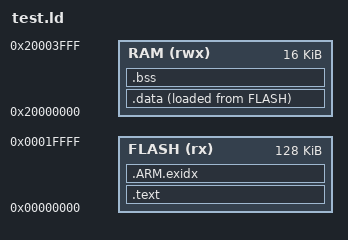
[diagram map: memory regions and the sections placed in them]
/* Test-only map shared by the selected QEMU machines, not a production MCU map. */
ENTRY(Reset_Handler)
MEMORY {
  FLASH(rx) : ORIGIN = 0x00000000, LENGTH = 128K
  RAM(rwx) : ORIGIN = 0x20000000, LENGTH = 16K
}
_estack = ORIGIN(RAM) + LENGTH(RAM);
SECTIONS {
  .text : { KEEP(*(.isr_vector)) *(.text*) *(.rodata*) } > FLASH
  .ARM.exidx : { *(.ARM.exidx*) } > FLASH
  .data : { . = ALIGN(4); _sdata = .; *(.data*) . = ALIGN(4); _edata = .; } > RAM AT> FLASH
  _sidata = LOADADDR(.data);
  .bss (NOLOAD) : { . = ALIGN(4); _sbss = .; *(.bss*) *(COMMON) . = ALIGN(4); _ebss = .; } > RAM
}
